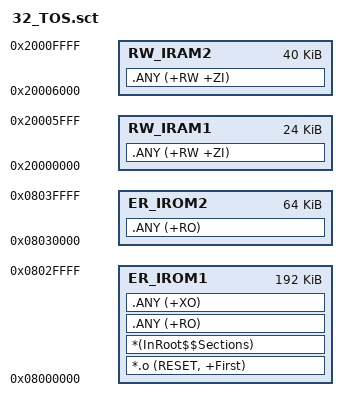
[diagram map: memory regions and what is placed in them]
; *************************************************************
; *** Scatter-Loading Description File generated by uVision ***
; *************************************************************

LR_IROM1 0x08000000 0x00030000  {    ; load region size_region
  ER_IROM1 0x08000000 0x00030000  {  ; load address = execution address
   *.o (RESET, +First)
   *(InRoot$$Sections)
   .ANY (+RO)
   .ANY (+XO)
  }
  RW_IRAM1 0x20000000 0x00006000  {  ; RW data
   .ANY (+RW +ZI)
  }
  RW_IRAM2 0x20006000 0x0000A000  {
   .ANY (+RW +ZI)
  }
}

LR_IROM2 0x08030000 0x00010000  {
  ER_IROM2 0x08030000 0x00010000  {  ; load address = execution address
   .ANY (+RO)
  }
}
